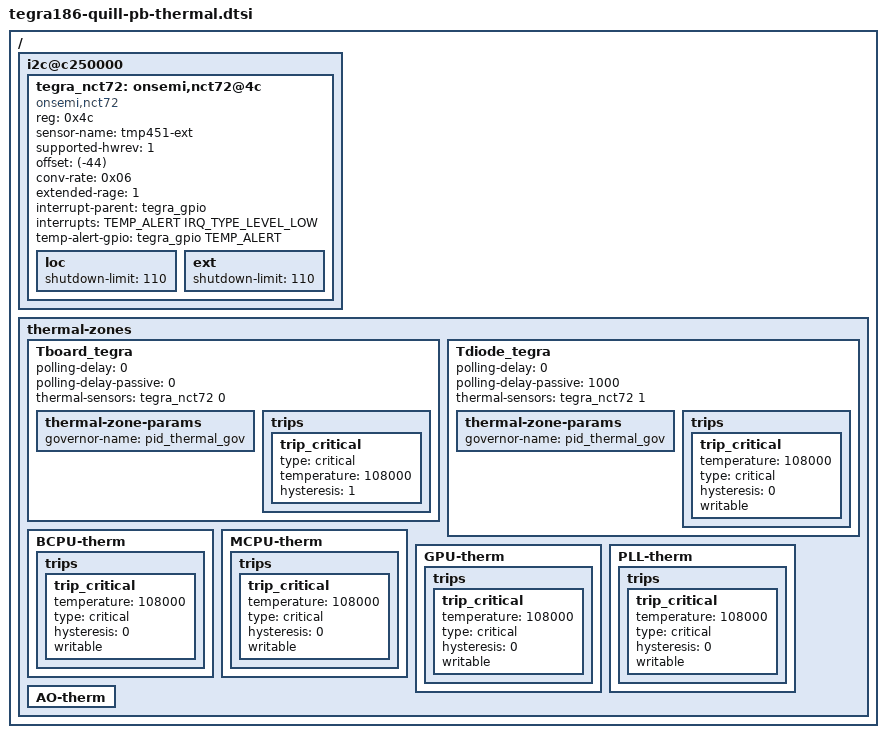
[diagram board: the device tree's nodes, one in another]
/*
 * Copyright (c) 2015, NVIDIA CORPORATION. All rights reserved.
 *
 * This program is free software; you can redistribute it and/or modify it
 * under the terms and conditions of the GNU General Public License,
 * version 2, as published by the Free Software Foundation.
 *
 * This program is distributed in the hope it will be useful, but WITHOUT
 * ANY WARRANTY; without even the implied warranty of MERCHANTABILITY or
 * FITNESS FOR A PARTICULAR PURPOSE.  See the GNU General Public License for
 * more details.
 *
 * You should have received a copy of the GNU General Public License
 * along with this program.  If not, see <http://www.gnu.org/licenses/>.
 */

#include <dt-bindings/interrupt-controller/arm-gic.h>
#include <dt-bindings/gpio/tegra-gpio.h>
#include <dt-bindings/thermal/thermal.h>

/* THERMAL gpio definitions */
#define TEMP_ALERT		TEGRA_GPIO(V, 0)

/ {
	i2c@c250000 {
		status = "okay";

		tegra_nct72: onsemi,nct72@4c {
			status = "okay";
			#thermal-sensor-cells = <1>;
			compatible = "onsemi,nct72";
			reg = <0x4c>;
			sensor-name = "tmp451-ext";
			supported-hwrev = <1>;
			offset = <(-44)>;
			conv-rate = <0x06>;
			extended-rage = <1>;

			interrupt-parent = <&tegra_gpio>;
			interrupts = <TEMP_ALERT IRQ_TYPE_LEVEL_LOW>;
			temp-alert-gpio = <&tegra_gpio TEMP_ALERT 0>;

			/* vdd-supply configured in power tree */
			loc {
				/* set to maximum for not having local  shutdown */
				shutdown-limit = <110>;
			};
			ext {
				shutdown-limit = <110>;
			};
		};
	};

	thermal-zones {
		status = "okay";

		Tboard_tegra {
			status = "okay";
			polling-delay = <0>;
			polling-delay-passive = <0>;
			thermal-sensors = <&tegra_nct72 0>;

			thermal-zone-params {
				governor-name = "pid_thermal_gov";
			};

			trips {
				trip_critical {
					type = "critical";
					temperature = <108000>;
					hysteresis = <1>;
				};
			};
		};

		Tdiode_tegra {
			status = "okay";
			polling-delay = <0>;
			polling-delay-passive = <1000>;
			thermal-sensors = <&tegra_nct72 1>;

			thermal-zone-params {
				governor-name = "pid_thermal_gov";
			};

			trips {
				trip_critical {
					/* keep this below HW shutdown to log alerts */
					temperature = <108000>;
					type = "critical";
					hysteresis = <0>;
					writable;
				};
			};
		};

		BCPU-therm {
			status = "okay";
			trips {
				trip_critical {
					temperature = <108000>;
					type = "critical";
					hysteresis = <0>;
					writable;
				};
			};
		};

		MCPU-therm {
			status = "okay";
			trips {
				trip_critical {
					temperature = <108000>;
					type = "critical";
					hysteresis = <0>;
					writable;
				};
			};
		};

		GPU-therm {
			status = "okay";
			trips {
				trip_critical {
					temperature = <108000>;
					type = "critical";
					hysteresis = <0>;
					writable;
				};
			};
		};

		PLL-therm {
			status = "okay";
			trips {
				trip_critical {
					temperature = <108000>;
					type = "critical";
					hysteresis = <0>;
					writable;
				};
			};
		};

		AO-therm {
			status = "okay";
		};

		BCPU-therm {
			status = "okay";
		};

		MCPU-therm {
			status = "okay";
		};

		GPU-therm {
			status = "okay";
		};

		PLL-therm {
			status = "okay";
		};
	};
};
